# intc register map
Vendor: Texas Instruments
Peripheral module from a debugger description file (folder Keystone).
Registers are 32-bit, read-write, no defined reset value unless marked. A register's access mark holds for its fields unless they carry their own. Offsets are as the file gives them; lines under a group give offsets from that group; [hi:lo] are bit positions; {n}, {i} and the like mark numbered series; 'fields as' and 'values as' point back to an identical list; <NAME> marks a mode.

## INTC3
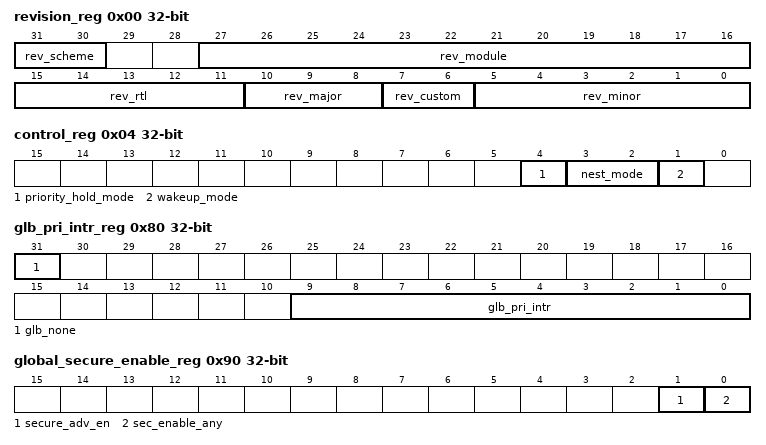
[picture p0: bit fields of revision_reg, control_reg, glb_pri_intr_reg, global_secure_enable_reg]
0x00 revision_reg
  [31:30] rev_scheme, [27:16] rev_module, [15:11] rev_rtl, [10:8] rev_major, [7:6] rev_custom, [5:0] rev_minor
0x04 control_reg
  [4] priority_hold_mode, [3:2] nest_mode, [1] wakeup_mode
0x0C host_control_reg
0x10 global_enable_hint_reg
  [0] enable_hint_any
0x1C glb_nest_level_reg
  [8:0] glb_nest_level
0x20 status_set_index_reg
  [9:0] status_set_index
0x24 status_clr_index_reg
  [9:0] status_clr_index
0x28 enable_set_index_reg
  [9:0] enable_set_index
0x2C enable_clr_index_reg
  [9:0] enable_clr_index
0x34 hint_enable_set_index_reg
  [7:0] hint_enable_set_index
0x38 hint_enable_clr_index_reg
  [7:0] hint_enable_clr_index
0x58 vector_null_reg
  [31:0] vector_null_addr
0x80 glb_pri_intr_reg
  [31] glb_none, [9:0] glb_pri_intr
0x84 glb_vector_addr_reg
  [31:0] glb_vector_addr
0x90 global_secure_enable_reg
  [1] secure_adv_en, [0] sec_enable_any
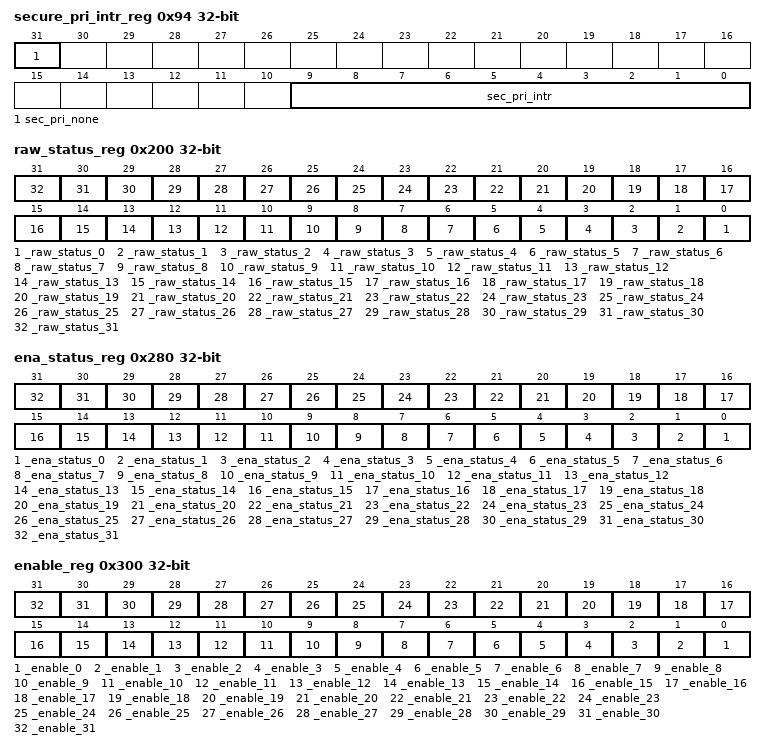
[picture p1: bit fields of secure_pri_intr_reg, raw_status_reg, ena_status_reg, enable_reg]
0x94 secure_pri_intr_reg
  [31] sec_pri_none, [9:0] sec_pri_intr
0x200 raw_status_reg — (1 of 32, stride 4)
  [n] _raw_status_{n} (n=0..31)
0x280 ena_status_reg — (1 of 32, stride 4)
  [n] _ena_status_{n} (n=0..31)
0x300 enable_reg — (1 of 32, stride 4)
  [n] _enable_{n} (n=0..31)
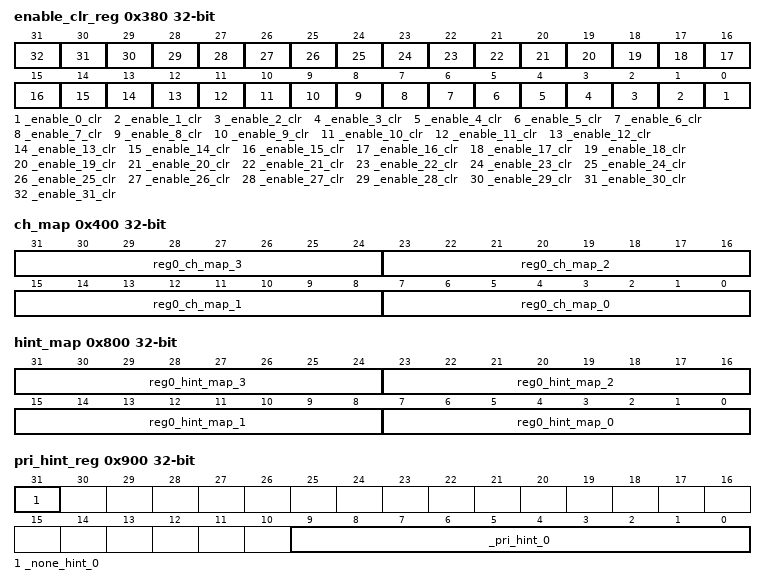
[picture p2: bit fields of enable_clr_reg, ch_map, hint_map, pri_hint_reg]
0x380 enable_clr_reg — (1 of 32, stride 4)
  [n] _enable_{n}_clr (n=0..31)
0x400 ch_map — (1 of 256, stride 4)
  [8n+7:8n] reg0_ch_map_{n} (n=0..3)
0x800 hint_map — (1 of 64, stride 4)
  [8n+7:8n] reg0_hint_map_{n} (n=0..3)
0x900 pri_hint_reg — (1 of 256, stride 4)
  [31] _none_hint_0, [9:0] _pri_hint_0
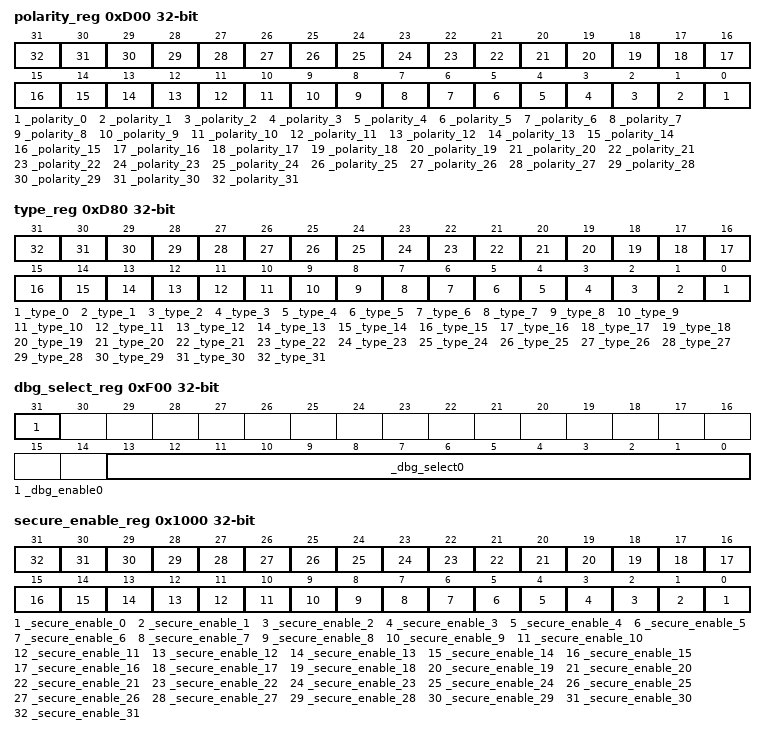
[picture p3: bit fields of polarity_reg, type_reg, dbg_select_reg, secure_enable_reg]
0xD00 polarity_reg — (1 of 32, stride 4)
  [n] _polarity_{n} (n=0..31)
0xD80 type_reg — (1 of 32, stride 4)
  [n] _type_{n} (n=0..31)
0xF00 dbg_select_reg — (1 of 64, stride 4)
  [31] _dbg_enable0, [13:0] _dbg_select0
0x1000 secure_enable_reg — (1 of 32, stride 4)
  [n] _secure_enable_{n} (n=0..31)
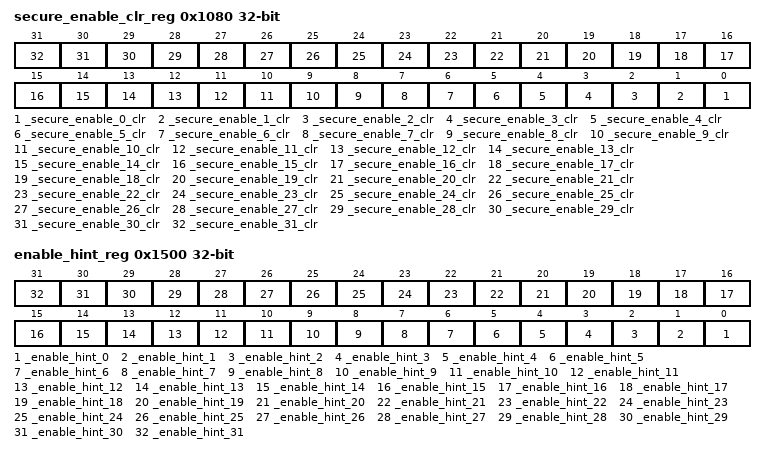
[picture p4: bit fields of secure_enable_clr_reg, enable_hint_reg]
0x1080 secure_enable_clr_reg — (1 of 32, stride 4)
  [n] _secure_enable_{n}_clr (n=0..31)
0x1100 nest_level_reg — (1 of 256, stride 4)
  [8:0] _nest_hint_0
0x1500 enable_hint_reg — (1 of 8, stride 4)
  [n] _enable_hint_{n} (n=0..31)
0x2000 vector_address_reg — (1 of 1024, stride 4)
  [31:0] vector_address_0
